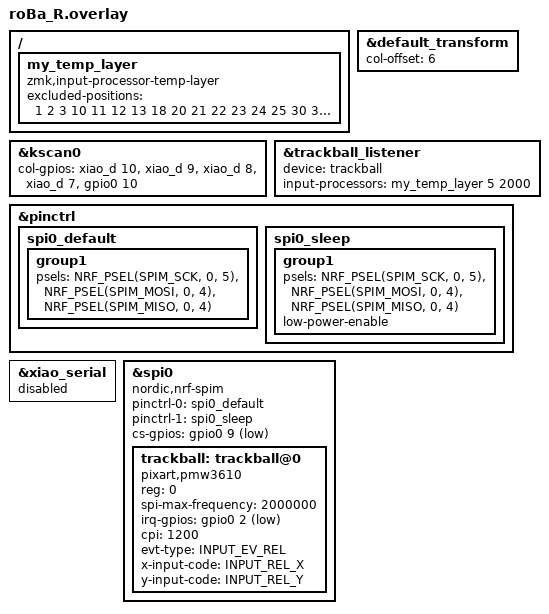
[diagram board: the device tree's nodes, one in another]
#include "roBa.dtsi"
#include <dt-bindings/zmk/pointing.h>
#include <zephyr/dt-bindings/input/input-event-codes.h>

&default_transform {
    col-offset = <6>;
};

&kscan0 {
    col-gpios
        = <&xiao_d 10 GPIO_ACTIVE_HIGH>
        , <&xiao_d 9 GPIO_ACTIVE_HIGH>
        , <&xiao_d 8 GPIO_ACTIVE_HIGH>
        , <&xiao_d 7 GPIO_ACTIVE_HIGH>
        , <&gpio0 10 GPIO_ACTIVE_HIGH>
        ;
};

/ {
    /* ▼ 存在しない機能を呼ばず、ここで自作の「オートマウス処理」を定義します ▼ */
    my_temp_layer: my_temp_layer {
        compatible = "zmk,input-processor-temp-layer";
        #input-processor-cells = <2>;
        /* 例外キー（クリックやコピペ等）の場所指定 */
        excluded-positions = <
            1 2 3 10 11 12 13 18 20 21 22 23 24 25 30 32 33
        >;
    };
};

/* ▼ roBa.dtsi にある trackball_listener に直接処理を追加します ▼ */
&trackball_listener {
    status = "okay";
    device = <&trackball>;
    /* ボールが動いたらレイヤー5(MOU)に切り替え、2秒(2000ms)経過で解除 */
    input-processors = <&my_temp_layer 5 2000>;
};

&pinctrl {
    spi0_default: spi0_default {
        group1 {
            psels = <NRF_PSEL(SPIM_SCK, 0, 5)>,
                <NRF_PSEL(SPIM_MOSI, 0, 4)>,
                <NRF_PSEL(SPIM_MISO, 0, 4)>;
        };
    };

    spi0_sleep: spi0_sleep {
        group1 {
            psels = <NRF_PSEL(SPIM_SCK, 0, 5)>,
                <NRF_PSEL(SPIM_MOSI, 0, 4)>,
                <NRF_PSEL(SPIM_MISO, 0, 4)>;
            low-power-enable;
        };
    };
};

&xiao_serial { status = "disabled"; };

&spi0 {
    status = "okay";
    compatible = "nordic,nrf-spim";
    pinctrl-0 = <&spi0_default>;
    pinctrl-1 = <&spi0_sleep>;
    pinctrl-names = "default", "sleep";
    cs-gpios = <&gpio0 9 GPIO_ACTIVE_LOW>;

    trackball: trackball@0 {
        status = "okay";
        compatible = "pixart,pmw3610";
        reg = <0>;
        spi-max-frequency = <2000000>;
        irq-gpios = <&gpio0 2 (GPIO_ACTIVE_LOW | GPIO_PULL_UP)>;
        
        cpi = <1200>;
        evt-type = <INPUT_EV_REL>;
        x-input-code = <INPUT_REL_X>;
        y-input-code = <INPUT_REL_Y>;
    };
};
